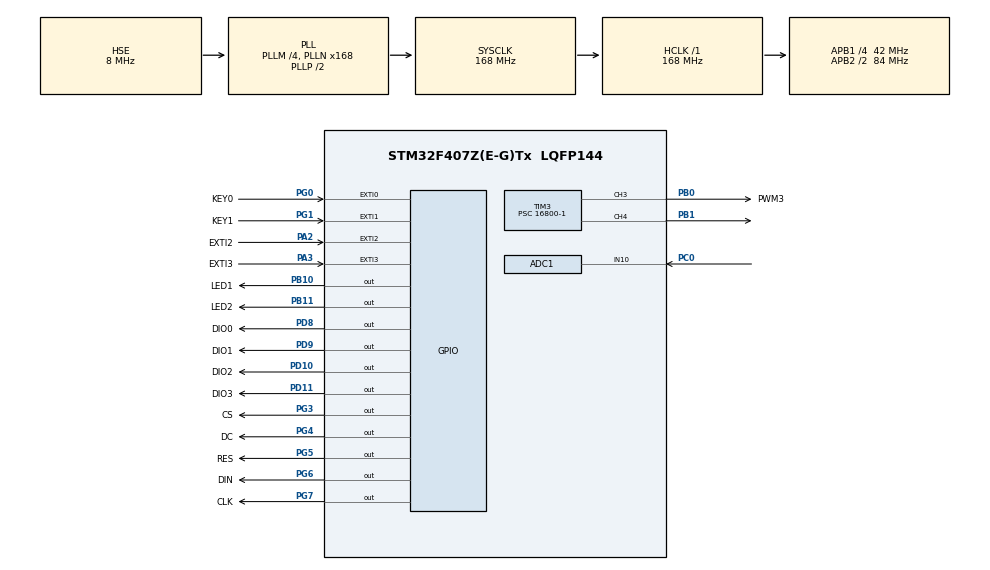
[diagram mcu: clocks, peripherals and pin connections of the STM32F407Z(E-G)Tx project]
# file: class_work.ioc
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ADC1.Channel-0\#ChannelRegularConversion=ADC_CHANNEL_10
ADC1.NbrOfConversionFlag=1
ADC1.Rank-0\#ChannelRegularConversion=1
ADC1.SamplingTime-0\#ChannelRegularConversion=ADC_SAMPLETIME_3CYCLES
ADC1.master=1
FREERTOS.Tasks01=FanTask,2,128,FanTask_Main,Default,NULL,Dynamic,NULL,NULL;OledTask,-2,128,Oled_Main,Default,NULL,Dynamic,NULL,NULL
FREERTOS.configENABLE_FPU=1
Mcu.Family=STM32F4
Mcu.Name=STM32F407Z(E-G)Tx
Mcu.Package=LQFP144
Mcu.UserConstants=TIM4_TICK_US,100
NVIC.EXTI0_IRQn=true\:5\:0\:false\:false\:true\:true\:true\:true\:true
NVIC.EXTI1_IRQn=true\:5\:0\:true\:false\:true\:true\:true\:true\:true
NVIC.EXTI2_IRQn=true\:5\:0\:false\:false\:true\:true\:true\:true\:true
NVIC.EXTI3_IRQn=true\:5\:0\:false\:false\:true\:true\:true\:true\:true
NVIC.PriorityGroup=NVIC_PRIORITYGROUP_4
NVIC.TIM1_TRG_COM_TIM11_IRQn=true\:5\:0\:false\:false\:true\:true\:true\:true\:true
NVIC.TIM4_IRQn=true\:5\:0\:false\:false\:true\:true\:true\:true\:true
NVIC.TIM7_IRQn=true\:15\:0\:false\:false\:true\:false\:false\:true\:true
NVIC.TIM8_TRG_COM_TIM14_IRQn=true\:5\:0\:false\:false\:true\:true\:true\:true\:true
NVIC.TIM8_UP_TIM13_IRQn=true\:5\:0\:false\:false\:true\:true\:true\:true\:true
NVIC.TimeBase=TIM7_IRQn
NVIC.TimeBaseIP=TIM7
PA13.Mode=Serial_Wire
PA13.Signal=SYS_JTMS-SWDIO
PA14.Mode=Serial_Wire
PA14.Signal=SYS_JTCK-SWCLK
PA2.GPIO_Label=EXTI2
PA2.Signal=GPXTI2
PA3.GPIO_Label=EXTI3
PA3.Signal=GPXTI3
PB0.GPIO_Label=PWM3
PB0.GPIO_PuPd=GPIO_PULLDOWN
PB0.GPIO_Speed=GPIO_SPEED_FREQ_VERY_HIGH
PB0.Signal=S_TIM3_CH3
PB1.Signal=S_TIM3_CH4
PB10.GPIO_Label=LED1
PB10.Signal=GPIO_Output
PB11.GPIO_Label=LED2
PB11.Signal=GPIO_Output
PC0.Signal=ADCx_IN10
PD10.GPIO_Label=DIO2
PD10.GPIO_Speed=GPIO_SPEED_FREQ_VERY_HIGH
PD10.Signal=GPIO_Output
PD11.GPIO_Label=DIO3
PD11.GPIO_Speed=GPIO_SPEED_FREQ_VERY_HIGH
PD11.Signal=GPIO_Output
PD8.GPIO_Label=DIO0
PD8.GPIO_Speed=GPIO_SPEED_FREQ_VERY_HIGH
PD8.Signal=GPIO_Output
PD9.GPIO_Label=DIO1
PD9.GPIO_Speed=GPIO_SPEED_FREQ_VERY_HIGH
PD9.Signal=GPIO_Output
PG0.GPIO_Label=KEY0
PG0.Signal=GPXTI0
PG1.GPIO_Label=KEY1
PG1.Signal=GPXTI1
PG3.GPIO_Label=CS
PG3.GPIO_Speed=GPIO_SPEED_FREQ_VERY_HIGH
PG3.Signal=GPIO_Output
PG4.GPIO_Label=DC
PG4.GPIO_Speed=GPIO_SPEED_FREQ_VERY_HIGH
PG4.Signal=GPIO_Output
PG5.GPIO_Label=RES
PG5.GPIO_Speed=GPIO_SPEED_FREQ_VERY_HIGH
PG5.Signal=GPIO_Output
PG6.GPIO_Label=DIN
PG6.GPIO_Speed=GPIO_SPEED_FREQ_VERY_HIGH
PG6.Signal=GPIO_Output
PG7.GPIO_Label=CLK
PG7.GPIO_Speed=GPIO_SPEED_FREQ_VERY_HIGH
PG7.Signal=GPIO_Output
PH0-OSC_IN.Mode=HSE-External-Oscillator
PH0-OSC_IN.Signal=RCC_OSC_IN
PH1-OSC_OUT.Mode=HSE-External-Oscillator
PH1-OSC_OUT.Signal=RCC_OSC_OUT
ProjectManager.HeapSize=0x200
ProjectManager.StackSize=0x400
ProjectManager.TargetToolchain=MDK-ARM V5
RCC.48MHZClocksFreq_Value=84000000
RCC.AHBFreq_Value=168000000
RCC.APB1CLKDivider=RCC_HCLK_DIV4
RCC.APB1Freq_Value=42000000
RCC.APB1TimFreq_Value=84000000
RCC.APB2CLKDivider=RCC_HCLK_DIV2
RCC.APB2Freq_Value=84000000
RCC.APB2TimFreq_Value=168000000
RCC.CortexFreq_Value=168000000
RCC.HCLKFreq_Value=168000000
RCC.HSE_VALUE=8000000
RCC.HSI_VALUE=16000000
RCC.LSE_VALUE=32768
RCC.PLLM=4
RCC.PLLN=168
RCC.PLLSourceVirtual=RCC_PLLSOURCE_HSE
RCC.SYSCLKFreq_VALUE=168000000
RCC.SYSCLKSource=RCC_SYSCLKSOURCE_PLLCLK
RCC.VCOOutputFreq_Value=336000000
SH.ADCx_IN10.0=ADC1_IN10,IN10
SH.S_TIM3_CH3.0=TIM3_CH3,PWM Generation3 CH3
SH.S_TIM3_CH4.0=TIM3_CH4,PWM Generation4 CH4
TIM11.Prescaler=168-1
TIM13.Period=500
TIM13.Prescaler=16800-1
TIM14.Period=10000
TIM14.Prescaler=16800-1
TIM3.AutoReloadPreload=TIM_AUTORELOAD_PRELOAD_ENABLE
TIM3.Channel-PWM\ Generation3\ CH3=TIM_CHANNEL_3
TIM3.Channel-PWM\ Generation4\ CH4=TIM_CHANNEL_4
TIM3.Period=255
TIM3.Prescaler=16800-1
TIM3.Pulse-PWM\ Generation3\ CH3=200
TIM4.Prescaler=16800-1
VP_FREERTOS_VS_CMSIS_V1.Mode=CMSIS_V1
VP_SYS_VS_tim7.Mode=TIM7
VP_TIM11_VS_ClockSourceINT.Mode=Enable_Timer
VP_TIM13_VS_ClockSourceINT.Mode=Enable_Timer
VP_TIM14_VS_ClockSourceINT.Mode=Enable_Timer
VP_TIM3_VS_ClockSourceINT.Mode=Internal
VP_TIM4_VS_ClockSourceINT.Mode=Internal
board=custom

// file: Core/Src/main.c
/* USER CODE BEGIN Header */
/**
  ******************************************************************************
  * @file           : main.c
  * @brief          : Main program body
  ******************************************************************************
  * @attention
  *
  * Copyright (c) 2024 STMicroelectronics.
  * All rights reserved.
  *
  * This software is licensed under terms that can be found in the LICENSE file
  * in the root directory of this software component.
  * If no LICENSE file comes with this software, it is provided AS-IS.
  *
  ******************************************************************************
  */
/* USER CODE END Header */
#include "main.h"
#include "cmsis_os.h"

/* USER CODE BEGIN Includes */
#include "FinalTask_StepMotor.h"
/* USER CODE END Includes */

ADC_HandleTypeDef hadc1;

TIM_HandleTypeDef htim3;
TIM_HandleTypeDef htim4;
TIM_HandleTypeDef htim11;
TIM_HandleTypeDef htim13;
TIM_HandleTypeDef htim14;

osThreadId FanTaskHandle;
osThreadId OledTaskHandle;

void SystemClock_Config(void);
static void MX_GPIO_Init(void);
static void MX_TIM3_Init(void);
static void MX_TIM14_Init(void);
static void MX_ADC1_Init(void);
static void MX_TIM13_Init(void);
static void MX_TIM11_Init(void);
static void MX_TIM4_Init(void);
void FanTask_Main(void const * argument);
void Oled_Main(void const * argument);

int main(void)
{

  /* MCU Configuration--------------------------------------------------------*/

  /* Reset of all peripherals, Initializes the Flash interface and the Systick. */
  HAL_Init();

  /* Configure the system clock */
  SystemClock_Config();

  /* Initialize all configured peripherals */
  MX_GPIO_Init();
  MX_TIM3_Init();
  MX_TIM14_Init();
  MX_ADC1_Init();
  MX_TIM13_Init();
  MX_TIM11_Init();
  MX_TIM4_Init();
  /* USER CODE BEGIN 2 */
	Final_Init_StepMotor();
  /* USER CODE END 2 */

  /* Create the thread(s) */
  /* definition and creation of FanTask */
  osThreadDef(FanTask, FanTask_Main, osPriorityHigh, 0, 128);
  FanTaskHandle = osThreadCreate(osThread(FanTask), NULL);

  /* definition and creation of OledTask */
  osThreadDef(OledTask, Oled_Main, osPriorityLow, 0, 128);
  OledTaskHandle = osThreadCreate(osThread(OledTask), NULL);

  /* Start scheduler */
  osKernelStart();

  /* We should never get here as control is now taken by the scheduler */
  /* Infinite loop */
  while (1)
  {

  }
}

void SystemClock_Config(void)
{
  RCC_OscInitTypeDef RCC_OscInitStruct = {0};
  RCC_ClkInitTypeDef RCC_ClkInitStruct = {0};

  /** Configure the main internal regulator output voltage
  */
  __HAL_RCC_PWR_CLK_ENABLE();
  __HAL_PWR_VOLTAGESCALING_CONFIG(PWR_REGULATOR_VOLTAGE_SCALE1);

  /** Initializes the RCC Oscillators according to the specified parameters
  * in the RCC_OscInitTypeDef structure.
  */
  RCC_OscInitStruct.OscillatorType = RCC_OSCILLATORTYPE_HSE;
  RCC_OscInitStruct.HSEState = RCC_HSE_ON;
  RCC_OscInitStruct.PLL.PLLState = RCC_PLL_ON;
  RCC_OscInitStruct.PLL.PLLSource = RCC_PLLSOURCE_HSE;
  RCC_OscInitStruct.PLL.PLLM = 4;
  RCC_OscInitStruct.PLL.PLLN = 168;
  RCC_OscInitStruct.PLL.PLLP = RCC_PLLP_DIV2;
  RCC_OscInitStruct.PLL.PLLQ = 4;
  if (HAL_RCC_OscConfig(&RCC_OscInitStruct) != HAL_OK)
  {
    Error_Handler();
  }

  /** Initializes the CPU, AHB and APB buses clocks
  */
  RCC_ClkInitStruct.ClockType = RCC_CLOCKTYPE_HCLK|RCC_CLOCKTYPE_SYSCLK
                              |RCC_CLOCKTYPE_PCLK1|RCC_CLOCKTYPE_PCLK2;
  RCC_ClkInitStruct.SYSCLKSource = RCC_SYSCLKSOURCE_PLLCLK;
  RCC_ClkInitStruct.AHBCLKDivider = RCC_SYSCLK_DIV1;
  RCC_ClkInitStruct.APB1CLKDivider = RCC_HCLK_DIV4;
  RCC_ClkInitStruct.APB2CLKDivider = RCC_HCLK_DIV2;

  if (HAL_RCC_ClockConfig(&RCC_ClkInitStruct, FLASH_LATENCY_5) != HAL_OK)
  {
    Error_Handler();
  }
}

static void MX_ADC1_Init(void)
{

  ADC_ChannelConfTypeDef sConfig = {0};

  /** Configure the global features of the ADC (Clock, Resolution, Data Alignment and number of conversion)
  */
  hadc1.Instance = ADC1;
  hadc1.Init.ClockPrescaler = ADC_CLOCK_SYNC_PCLK_DIV4;
  hadc1.Init.Resolution = ADC_RESOLUTION_12B;
  hadc1.Init.ScanConvMode = DISABLE;
  hadc1.Init.ContinuousConvMode = DISABLE;
  hadc1.Init.DiscontinuousConvMode = DISABLE;
  hadc1.Init.ExternalTrigConvEdge = ADC_EXTERNALTRIGCONVEDGE_NONE;
  hadc1.Init.ExternalTrigConv = ADC_SOFTWARE_START;
  hadc1.Init.DataAlign = ADC_DATAALIGN_RIGHT;
  hadc1.Init.NbrOfConversion = 1;
  hadc1.Init.DMAContinuousRequests = DISABLE;
  hadc1.Init.EOCSelection = ADC_EOC_SINGLE_CONV;
  if (HAL_ADC_Init(&hadc1) != HAL_OK)
  {
    Error_Handler();
  }

  /** Configure for the selected ADC regular channel its corresponding rank in the sequencer and its sample time.
  */
  sConfig.Channel = ADC_CHANNEL_10;
  sConfig.Rank = 1;
  sConfig.SamplingTime = ADC_SAMPLETIME_3CYCLES;
  if (HAL_ADC_ConfigChannel(&hadc1, &sConfig) != HAL_OK)
  {
    Error_Handler();
  }

}

static void MX_TIM3_Init(void)
{

  TIM_ClockConfigTypeDef sClockSourceConfig = {0};
  TIM_MasterConfigTypeDef sMasterConfig = {0};
  TIM_OC_InitTypeDef sConfigOC = {0};

  htim3.Instance = TIM3;
  htim3.Init.Prescaler = 16800-1;
  htim3.Init.CounterMode = TIM_COUNTERMODE_UP;
  htim3.Init.Period = 255;
  htim3.Init.ClockDivision = TIM_CLOCKDIVISION_DIV1;
  htim3.Init.AutoReloadPreload = TIM_AUTORELOAD_PRELOAD_ENABLE;
  if (HAL_TIM_Base_Init(&htim3) != HAL_OK)
  {
    Error_Handler();
  }
  sClockSourceConfig.ClockSource = TIM_CLOCKSOURCE_INTERNAL;
  if (HAL_TIM_ConfigClockSource(&htim3, &sClockSourceConfig) != HAL_OK)
  {
    Error_Handler();
  }
  if (HAL_TIM_PWM_Init(&htim3) != HAL_OK)
  {
    Error_Handler();
  }
  sMasterConfig.MasterOutputTrigger = TIM_TRGO_RESET;
  sMasterConfig.MasterSlaveMode = TIM_MASTERSLAVEMODE_DISABLE;
  if (HAL_TIMEx_MasterConfigSynchronization(&htim3, &sMasterConfig) != HAL_OK)
  {
    Error_Handler();
  }
  sConfigOC.OCMode = TIM_OCMODE_PWM1;
  sConfigOC.Pulse = 200;
  sConfigOC.OCPolarity = TIM_OCPOLARITY_HIGH;
  sConfigOC.OCFastMode = TIM_OCFAST_DISABLE;
  if (HAL_TIM_PWM_ConfigChannel(&htim3, &sConfigOC, TIM_CHANNEL_3) != HAL_OK)
  {
    Error_Handler();
  }
  sConfigOC.Pulse = 0;
  if (HAL_TIM_PWM_ConfigChannel(&htim3, &sConfigOC, TIM_CHANNEL_4) != HAL_OK)
  {
    Error_Handler();
  }
  HAL_TIM_MspPostInit(&htim3);

}

static void MX_TIM4_Init(void)
{

  TIM_ClockConfigTypeDef sClockSourceConfig = {0};
  TIM_MasterConfigTypeDef sMasterConfig = {0};

  htim4.Instance = TIM4;
  htim4.Init.Prescaler = 16800-1;
  htim4.Init.CounterMode = TIM_COUNTERMODE_UP;
  htim4.Init.Period = 65535;
  htim4.Init.ClockDivision = TIM_CLOCKDIVISION_DIV1;
  htim4.Init.AutoReloadPreload = TIM_AUTORELOAD_PRELOAD_DISABLE;
  if (HAL_TIM_Base_Init(&htim4) != HAL_OK)
  {
    Error_Handler();
  }
  sClockSourceConfig.ClockSource = TIM_CLOCKSOURCE_INTERNAL;
  if (HAL_TIM_ConfigClockSource(&htim4, &sClockSourceConfig) != HAL_OK)
  {
    Error_Handler();
  }
  sMasterConfig.MasterOutputTrigger = TIM_TRGO_RESET;
  sMasterConfig.MasterSlaveMode = TIM_MASTERSLAVEMODE_DISABLE;
  if (HAL_TIMEx_MasterConfigSynchronization(&htim4, &sMasterConfig) != HAL_OK)
  {
    Error_Handler();
  }

}

static void MX_TIM11_Init(void)
{

  htim11.Instance = TIM11;
  htim11.Init.Prescaler = 168-1;
  htim11.Init.CounterMode = TIM_COUNTERMODE_UP;
  htim11.Init.Period = 65535;
  htim11.Init.ClockDivision = TIM_CLOCKDIVISION_DIV1;
  htim11.Init.AutoReloadPreload = TIM_AUTORELOAD_PRELOAD_DISABLE;
  if (HAL_TIM_Base_Init(&htim11) != HAL_OK)
  {
    Error_Handler();
  }

}

static void MX_TIM13_Init(void)
{

  htim13.Instance = TIM13;
  htim13.Init.Prescaler = 16800-1;
  htim13.Init.CounterMode = TIM_COUNTERMODE_UP;
  htim13.Init.Period = 500;
  htim13.Init.ClockDivision = TIM_CLOCKDIVISION_DIV1;
  htim13.Init.AutoReloadPreload = TIM_AUTORELOAD_PRELOAD_DISABLE;
  if (HAL_TIM_Base_Init(&htim13) != HAL_OK)
  {
    Error_Handler();
  }

}

static void MX_TIM14_Init(void)
{

  htim14.Instance = TIM14;
  htim14.Init.Prescaler = 16800-1;
  htim14.Init.CounterMode = TIM_COUNTERMODE_UP;
  htim14.Init.Period = 10000;
  htim14.Init.ClockDivision = TIM_CLOCKDIVISION_DIV1;
  htim14.Init.AutoReloadPreload = TIM_AUTORELOAD_PRELOAD_DISABLE;
  if (HAL_TIM_Base_Init(&htim14) != HAL_OK)
  {
    Error_Handler();
  }

}

static void MX_GPIO_Init(void)
{
  GPIO_InitTypeDef GPIO_InitStruct = {0};

  /* GPIO Ports Clock Enable */
  __HAL_RCC_GPIOH_CLK_ENABLE();
  __HAL_RCC_GPIOC_CLK_ENABLE();
  __HAL_RCC_GPIOA_CLK_ENABLE();
  __HAL_RCC_GPIOB_CLK_ENABLE();
  __HAL_RCC_GPIOG_CLK_ENABLE();
  __HAL_RCC_GPIOD_CLK_ENABLE();

  /*Configure GPIO pin Output Level */
  HAL_GPIO_WritePin(GPIOB, LED1_Pin|LED2_Pin, GPIO_PIN_RESET);

  /*Configure GPIO pin Output Level */
  HAL_GPIO_WritePin(GPIOD, DIO0_Pin|DIO1_Pin|DIO2_Pin|DIO3_Pin, GPIO_PIN_RESET);

  /*Configure GPIO pin Output Level */
  HAL_GPIO_WritePin(GPIOG, CS_Pin|DC_Pin|RES_Pin|DIN_Pin
                          |CLK_Pin, GPIO_PIN_RESET);

  /*Configure GPIO pins : EXTI2_Pin EXTI3_Pin */
  GPIO_InitStruct.Pin = EXTI2_Pin|EXTI3_Pin;
  GPIO_InitStruct.Mode = GPIO_MODE_IT_RISING;
  GPIO_InitStruct.Pull = GPIO_NOPULL;
  HAL_GPIO_Init(GPIOA, &GPIO_InitStruct);

  /*Configure GPIO pins : KEY0_Pin KEY1_Pin */
  GPIO_InitStruct.Pin = KEY0_Pin|KEY1_Pin;
  GPIO_InitStruct.Mode = GPIO_MODE_IT_RISING;
  GPIO_InitStruct.Pull = GPIO_NOPULL;
  HAL_GPIO_Init(GPIOG, &GPIO_InitStruct);

  /*Configure GPIO pins : LED1_Pin LED2_Pin */
  GPIO_InitStruct.Pin = LED1_Pin|LED2_Pin;
  GPIO_InitStruct.Mode = GPIO_MODE_OUTPUT_PP;
  GPIO_InitStruct.Pull = GPIO_NOPULL;
  GPIO_InitStruct.Speed = GPIO_SPEED_FREQ_LOW;
  HAL_GPIO_Init(GPIOB, &GPIO_InitStruct);

  /*Configure GPIO pins : DIO0_Pin DIO1_Pin DIO2_Pin DIO3_Pin */
  GPIO_InitStruct.Pin = DIO0_Pin|DIO1_Pin|DIO2_Pin|DIO3_Pin;
  GPIO_InitStruct.Mode = GPIO_MODE_OUTPUT_PP;
  GPIO_InitStruct.Pull = GPIO_NOPULL;
  GPIO_InitStruct.Speed = GPIO_SPEED_FREQ_VERY_HIGH;
  HAL_GPIO_Init(GPIOD, &GPIO_InitStruct);

  /*Configure GPIO pins : CS_Pin DC_Pin RES_Pin DIN_Pin
                           CLK_Pin */
  GPIO_InitStruct.Pin = CS_Pin|DC_Pin|RES_Pin|DIN_Pin
                          |CLK_Pin;
  GPIO_InitStruct.Mode = GPIO_MODE_OUTPUT_PP;
  GPIO_InitStruct.Pull = GPIO_NOPULL;
  GPIO_InitStruct.Speed = GPIO_SPEED_FREQ_VERY_HIGH;
  HAL_GPIO_Init(GPIOG, &GPIO_InitStruct);

  /* EXTI interrupt init*/
  HAL_NVIC_SetPriority(EXTI0_IRQn, 5, 0);
  HAL_NVIC_EnableIRQ(EXTI0_IRQn);

  HAL_NVIC_SetPriority(EXTI1_IRQn, 5, 0);
  HAL_NVIC_EnableIRQ(EXTI1_IRQn);

  HAL_NVIC_SetPriority(EXTI2_IRQn, 5, 0);
  HAL_NVIC_EnableIRQ(EXTI2_IRQn);

  HAL_NVIC_SetPriority(EXTI3_IRQn, 5, 0);
  HAL_NVIC_EnableIRQ(EXTI3_IRQn);

}

/* USER CODE BEGIN 4 */
float fan_test_rpm=33.0f;
/* USER CODE END 4 */

void FanTask_Main(void const * argument)
{
  /* USER CODE BEGIN 5 */
  /* Infinite loop */
  for(;;)
  {
		Final_Main_StepMotor();
    osDelay(1);
  }
  /* USER CODE END 5 */
}

void Oled_Main(void const * argument)
{
  /* USER CODE BEGIN Oled_Main */
  /* Infinite loop */
  for(;;)
  {
		Final_Disp_StepMotor();
    osDelay(100);
  }
  /* USER CODE END Oled_Main */
}

void HAL_TIM_PeriodElapsedCallback(TIM_HandleTypeDef *htim)
{
  /* USER CODE BEGIN Callback 0 */
	FinalTask_TIM_PeriodElapsedCallback(htim);
  /* USER CODE END Callback 0 */
  if (htim->Instance == TIM7) {
    HAL_IncTick();
  }
  /* USER CODE BEGIN Callback 1 */
	Timetick_Callback(htim);
  /* USER CODE END Callback 1 */
}

void Error_Handler(void)
{
  __disable_irq();
  while (1)
  {
  }
}
